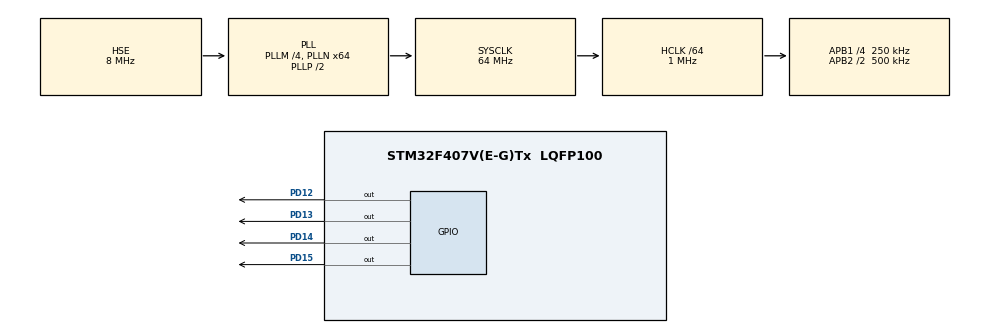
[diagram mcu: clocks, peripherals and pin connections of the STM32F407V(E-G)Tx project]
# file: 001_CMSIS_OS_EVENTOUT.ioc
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Mcu.Family=STM32F4
Mcu.Name=STM32F407V(E-G)Tx
Mcu.Package=LQFP100
NVIC.PriorityGroup=NVIC_PRIORITYGROUP_0
PD0.GPIO_Speed=GPIO_SPEED_FREQ_VERY_HIGH
PD0.Signal=EVENTOUT
PD1.Signal=EVENTOUT
PD12.Signal=GPIO_Output
PD13.Signal=GPIO_Output
PD14.Signal=GPIO_Output
PD15.Signal=GPIO_Output
PH0-OSC_IN.Mode=HSE-External-Oscillator
PH0-OSC_IN.Signal=RCC_OSC_IN
PH1-OSC_OUT.Mode=HSE-External-Oscillator
PH1-OSC_OUT.Signal=RCC_OSC_OUT
ProjectManager.HeapSize=0x200
ProjectManager.StackSize=0x400
ProjectManager.TargetToolchain=STM32CubeIDE
RCC.48MHZClocksFreq_Value=18285714.285714287
RCC.AHBCLKDivider=RCC_SYSCLK_DIV64
RCC.AHBFreq_Value=1000000
RCC.APB1CLKDivider=RCC_HCLK_DIV4
RCC.APB1Freq_Value=250000
RCC.APB1TimFreq_Value=500000
RCC.APB2CLKDivider=RCC_HCLK_DIV2
RCC.APB2Freq_Value=500000
RCC.APB2TimFreq_Value=1000000
RCC.CortexFreq_Value=1000000
RCC.HCLKFreq_Value=1000000
RCC.HSE_VALUE=8000000
RCC.HSI_VALUE=16000000
RCC.LSE_VALUE=32768
RCC.PLLM=4
RCC.PLLN=64
RCC.PLLQ=7
RCC.PLLSourceVirtual=RCC_PLLSOURCE_HSE
RCC.SYSCLKFreq_VALUE=64000000
RCC.SYSCLKSource=RCC_SYSCLKSOURCE_PLLCLK
RCC.VCOOutputFreq_Value=128000000
board=STM32F407G-DISC1

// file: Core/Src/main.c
/* USER CODE BEGIN Header */
/**
  ******************************************************************************
  * @file           : main.c
  * @brief          : Main program body
  ******************************************************************************
  * @attention
  *
  * Copyright (c) 2023 STMicroelectronics.
  * All rights reserved.
  *
  * This software is licensed under terms that can be found in the LICENSE file
  * in the root directory of this software component.
  * If no LICENSE file comes with this software, it is provided AS-IS.
  *
  ******************************************************************************
  */
/* USER CODE END Header */
#include "main.h"

void SystemClock_Config(void);
static void MX_GPIO_Init(void);

int main(void)
{

  /* MCU Configuration--------------------------------------------------------*/

  /* Reset of all peripherals, Initializes the Flash interface and the Systick. */
  HAL_Init();

  /* Configure the system clock */
  SystemClock_Config();

  /* Initialize all configured peripherals */
  MX_GPIO_Init();

  /* Infinite loop */
  while (1)
  {

    /* USER CODE BEGIN 3 */
	  __asm__ volatile ("sev");
	  //__SEV();
	  HAL_Delay(500);
  }
  /* USER CODE END 3 */
}

void SystemClock_Config(void)
{
  RCC_OscInitTypeDef RCC_OscInitStruct = {0};
  RCC_ClkInitTypeDef RCC_ClkInitStruct = {0};

  /** Configure the main internal regulator output voltage
  */
  __HAL_RCC_PWR_CLK_ENABLE();
  __HAL_PWR_VOLTAGESCALING_CONFIG(PWR_REGULATOR_VOLTAGE_SCALE1);

  /** Initializes the RCC Oscillators according to the specified parameters
  * in the RCC_OscInitTypeDef structure.
  */
  RCC_OscInitStruct.OscillatorType = RCC_OSCILLATORTYPE_HSE;
  RCC_OscInitStruct.HSEState = RCC_HSE_ON;
  RCC_OscInitStruct.PLL.PLLState = RCC_PLL_ON;
  RCC_OscInitStruct.PLL.PLLSource = RCC_PLLSOURCE_HSE;
  RCC_OscInitStruct.PLL.PLLM = 4;
  RCC_OscInitStruct.PLL.PLLN = 64;
  RCC_OscInitStruct.PLL.PLLP = RCC_PLLP_DIV2;
  RCC_OscInitStruct.PLL.PLLQ = 7;
  if (HAL_RCC_OscConfig(&RCC_OscInitStruct) != HAL_OK)
  {
    Error_Handler();
  }

  /** Initializes the CPU, AHB and APB buses clocks
  */
  RCC_ClkInitStruct.ClockType = RCC_CLOCKTYPE_HCLK|RCC_CLOCKTYPE_SYSCLK
                              |RCC_CLOCKTYPE_PCLK1|RCC_CLOCKTYPE_PCLK2;
  RCC_ClkInitStruct.SYSCLKSource = RCC_SYSCLKSOURCE_PLLCLK;
  RCC_ClkInitStruct.AHBCLKDivider = RCC_SYSCLK_DIV64;
  RCC_ClkInitStruct.APB1CLKDivider = RCC_HCLK_DIV4;
  RCC_ClkInitStruct.APB2CLKDivider = RCC_HCLK_DIV2;

  if (HAL_RCC_ClockConfig(&RCC_ClkInitStruct, FLASH_LATENCY_0) != HAL_OK)
  {
    Error_Handler();
  }
}

static void MX_GPIO_Init(void)
{
  GPIO_InitTypeDef GPIO_InitStruct = {0};

  /* GPIO Ports Clock Enable */
  __HAL_RCC_GPIOH_CLK_ENABLE();
  __HAL_RCC_GPIOD_CLK_ENABLE();

  /*Configure GPIO pin Output Level */
  HAL_GPIO_WritePin(GPIOD, GPIO_PIN_12|GPIO_PIN_13|GPIO_PIN_14|GPIO_PIN_15, GPIO_PIN_RESET);

  /*Configure GPIO pins : PD12 PD13 PD14 PD15 */
  GPIO_InitStruct.Pin = GPIO_PIN_12|GPIO_PIN_13|GPIO_PIN_14|GPIO_PIN_15;
  GPIO_InitStruct.Mode = GPIO_MODE_OUTPUT_PP;
  GPIO_InitStruct.Pull = GPIO_NOPULL;
  GPIO_InitStruct.Speed = GPIO_SPEED_FREQ_LOW;
  HAL_GPIO_Init(GPIOD, &GPIO_InitStruct);

  /*Configure GPIO pin : PD0 */
  GPIO_InitStruct.Pin = GPIO_PIN_0;
  GPIO_InitStruct.Mode = GPIO_MODE_AF_PP;
  GPIO_InitStruct.Pull = GPIO_NOPULL;
  GPIO_InitStruct.Speed = GPIO_SPEED_FREQ_VERY_HIGH;
  GPIO_InitStruct.Alternate = GPIO_AF15_EVENTOUT;
  HAL_GPIO_Init(GPIOD, &GPIO_InitStruct);

  /*Configure GPIO pin : PD1 */
  GPIO_InitStruct.Pin = GPIO_PIN_1;
  GPIO_InitStruct.Mode = GPIO_MODE_AF_PP;
  GPIO_InitStruct.Pull = GPIO_NOPULL;
  GPIO_InitStruct.Speed = GPIO_SPEED_FREQ_LOW;
  GPIO_InitStruct.Alternate = GPIO_AF15_EVENTOUT;
  HAL_GPIO_Init(GPIOD, &GPIO_InitStruct);

}

void Error_Handler(void)
{
  __disable_irq();
  while (1)
  {
  }
}
